# RK3399-AP register map
File version: 1
CPU: CA7 r0p1, little endian, MPU, FPU, I-cache, D-cache, VTOR, 4 interrupt priority bits, 0 interrupts
Registers are 32-bit, read-write, reset 0x0 unless marked. A register's access mark holds for its fields unless they carry their own. Offsets are from the block's base; [hi:lo] are bit positions; {n}, {i} and the like mark numbered series; 'fields as' and 'values as' point back to an identical list.

## GRF (part 4 of 4)
Base 0xFF770000
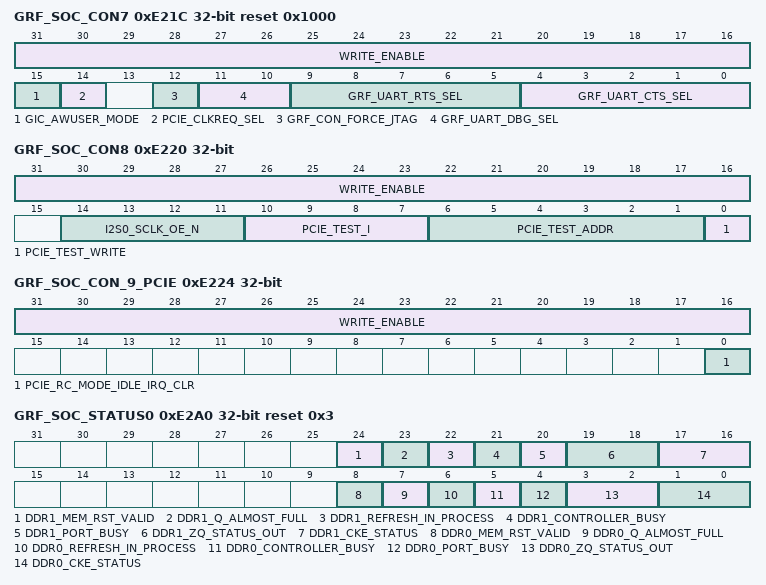
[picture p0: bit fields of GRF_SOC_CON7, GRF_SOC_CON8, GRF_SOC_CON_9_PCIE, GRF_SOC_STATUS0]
0xE21C GRF_SOC_CON7 reset 0x1000 — SoC control register 7
  [31:16] WRITE_ENABLE — bit0~15 write enable When bit 16=1, bit 0 can be written by software . When bit 16=0, bit 0 cannot be written by software; When bit 17=1, bit 1 can be written by software . When bit 17=0, bit 1 cannot be written by software; ...... When bit 31=1, bit 15 can be written by software . When bit 31=0, bit 15 cannot be written by software;
  [15] GIC_AWUSER_MODE — gic_awuser mode select 1: address mode 0: user mode
  [14] PCIE_CLKREQ_SEL — pcie_clkreq_sel port control
  [12] GRF_CON_FORCE_JTAG
  [11:10] GRF_UART_DBG_SEL
  [9:5] GRF_UART_RTS_SEL — uart_rts_sel bit control UART polarity selection for rts port Every bit for one UART. 1\'b1: invert uart_rts_n 1\'b0: keep the rts_n value from UART module output
  [4:0] GRF_UART_CTS_SEL — UART polarity selection for cts port Every bit for one UART. 1\'b1: invert uart_cts_n 1\'b0: keep the cts_n value from IO
0xE220 GRF_SOC_CON8 — SoC control register 8
  [31:16] WRITE_ENABLE — bit0~15 write enable When bit 16=1, bit 0 can be written by software . When bit 16=0, bit 0 cannot be written by software; When bit 17=1, bit 1 can be written by software . When bit 17=0, bit 1 cannot be written by software; ...... When bit 31=1, bit 15 can be written by software . When bit 31=0, bit 15 cannot be written by software;
  [14:11] I2S0_SCLK_OE_N — i2s0_sclk_oe_n bit control
  [10:7] PCIE_TEST_I — pci test input
  [6:1] PCIE_TEST_ADDR — pci test address control
  [0] PCIE_TEST_WRITE — pcie test write control 1\'b0: disable 1\'b1: enable
0xE224 GRF_SOC_CON_9_PCIE — SoC control register 9 for PCIE
  [31:16] WRITE_ENABLE — bit0~15 write enable When bit 16=1, bit 0 can be written by software . When bit 16=0, bit 0 cannot be written by software; When bit 17=1, bit 1 can be written by software . When bit 17=0, bit 1 cannot be written by software; ...... When bit 31=1, bit 15 can be written by software . When bit 31=0, bit 15 cannot be written by software;
  [0] PCIE_RC_MODE_IDLE_IRQ_CLR — irq clear bit for pcie_rc_mode_idle_irq
0xE2A0 GRF_SOC_STATUS0 reset 0x3 — SOC status register 0
  [24] DDR1_MEM_RST_VALID — status bit of ddr1_mem_rst_valid
  [23] DDR1_Q_ALMOST_FULL — status bit of ddr1_q_almost_full
  [22] DDR1_REFRESH_IN_PROCESS — status bit of ddr1_refresh_in_process
  [21] DDR1_CONTROLLER_BUSY — status bit of ddr1_controller_busy
  [20] DDR1_PORT_BUSY — status bit of ddr1_port_busy
  [19:18] DDR1_ZQ_STATUS_OUT — status bit of ddr1_zq_status_out
  [17:16] DDR1_CKE_STATUS — status bit of ddr1_cke_status
  [8] DDR0_MEM_RST_VALID — status bit of ddr0_mem_rst_valid
  [7] DDR0_Q_ALMOST_FULL — status bit of ddr0_q_almost_full
  [6] DDR0_REFRESH_IN_PROCESS — status bit of ddr0_refresh_in_process
  [5] DDR0_CONTROLLER_BUSY — status bit of ddr0_controller_busy
  [4] DDR0_PORT_BUSY — status bit of ddr0_port_busy
  [3:2] DDR0_ZQ_STATUS_OUT — status bit of ddr0_zq_status_out
  [1:0] DDR0_CKE_STATUS — status bit of ddr0_cke_status
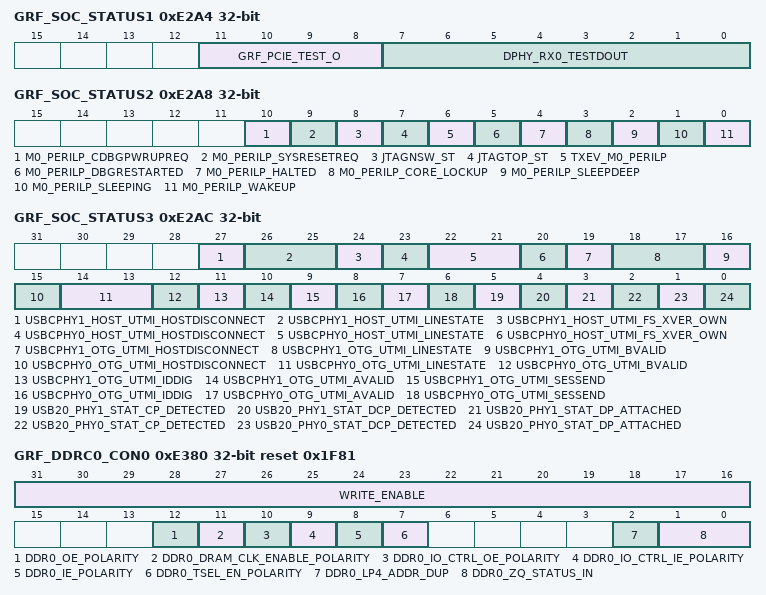
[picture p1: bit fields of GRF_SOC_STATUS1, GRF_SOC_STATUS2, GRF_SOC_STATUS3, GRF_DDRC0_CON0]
0xE2A4 GRF_SOC_STATUS1 — SOC status register 1
  [11:8] GRF_PCIE_TEST_O — status bit of grf_pcie_test_o
  [7:0] DPHY_RX0_TESTDOUT — status bit of dphy_rx0_testdout
0xE2A8 GRF_SOC_STATUS2 — SOC status register 2
  [10] M0_PERILP_CDBGPWRUPREQ — m0_perilp_cdbgpwrupreq status bit
  [9] M0_PERILP_SYSRESETREQ
  [8] JTAGNSW_ST — status bit of jtagnsw_st
  [7] JTAGTOP_ST — status bit of jtagtop_st
  [6] TXEV_M0_PERILP — status bit of xev_m0_perilp
  [5] M0_PERILP_DBGRESTARTED — status bit of m0_perilp_dbgrestarted
  [4] M0_PERILP_HALTED — status bit of m0_perilp_halted
  [3] M0_PERILP_CORE_LOCKUP — status bit of m0_perilp_core_lockup
  [2] M0_PERILP_SLEEPDEEP — status bit of m0_perilp_sleeping
  [1] M0_PERILP_SLEEPING — status bit of m0_perilp_sleeping
  [0] M0_PERILP_WAKEUP — status bit of m0_perilp_wakeup
0xE2AC GRF_SOC_STATUS3 access per field — SOC status register 3
  [27] USBCPHY1_HOST_UTMI_HOSTDISCONNECT ro — usbcphy1_host_utmi_hostdisconnect status
  [26:25] USBCPHY1_HOST_UTMI_LINESTATE ro — usbcphy1_host_utmi_linestate status
  [24] USBCPHY1_HOST_UTMI_FS_XVER_OWN ro — 1: ohci owns usb2phy 0: ehci owns usb2phy
  [23] USBCPHY0_HOST_UTMI_HOSTDISCONNECT ro — usbcphy0_host_utmi_hostdisconnect status
  [22:21] USBCPHY0_HOST_UTMI_LINESTATE ro — usbcphy0_host_utmi_linestate status
  [20] USBCPHY0_HOST_UTMI_FS_XVER_OWN ro — 1: ohci owns usb2phy 0: ehci owns usb2phy
  [19] USBCPHY1_OTG_UTMI_HOSTDISCONNECT ro — usbcphy1_otg_utmi_hostdisconnect status
  [18:17] USBCPHY1_OTG_UTMI_LINESTATE ro — usbcphy1_otg_utmi_linestate status bit
  [16] USBCPHY1_OTG_UTMI_BVALID ro — usbcphy1_otg_utmi_bvalid status bit
  [15] USBCPHY0_OTG_UTMI_HOSTDISCONNECT ro — usbcphy0_otg_utmi_hostdisconnect status
  [14:13] USBCPHY0_OTG_UTMI_LINESTATE ro — usbcphy0_otg_utmi_linestate status bit
  [12] USBCPHY0_OTG_UTMI_BVALID ro — usbcphy0_otg_utmi_bvalid status bit
  [11] USBCPHY1_OTG_UTMI_IDDIG rw — usbcphy1_otg_utmi_iddig status bit
  [10] USBCPHY1_OTG_UTMI_AVALID rw — usbcphy1_otg_utmi_avalid status bit
  [9] USBCPHY1_OTG_UTMI_SESSEND rw — usbcphy1_otg_utmi_sessend status bit
  [8] USBCPHY0_OTG_UTMI_IDDIG rw — usbcphy0_otg_utmi_iddig status bit
  [7] USBCPHY0_OTG_UTMI_AVALID rw — usbcphy0_otg_utmi_avalid status bit
  [6] USBCPHY0_OTG_UTMI_SESSEND rw — usbcphy0_otg_utmi_sessend status bit
  [5] USB20_PHY1_STAT_CP_DETECTED rw — usb20_phy1_stat_cp_detected status bit
  [4] USB20_PHY1_STAT_DCP_DETECTED rw — usb20_phy1_stat_dcp_detected status bit
  [3] USB20_PHY1_STAT_DP_ATTACHED rw — usb20_phy1_stat_dp_attached status bit
  [2] USB20_PHY0_STAT_CP_DETECTED rw — usb20_phy0_stat_cp_detected status bit
  [1] USB20_PHY0_STAT_DCP_DETECTED rw — usb20_phy0_stat_dcp_detected status bit
  [0] USB20_PHY0_STAT_DP_ATTACHED rw — usb20_phy0_stat_dp_attached status bit
0xE2B0 GRF_SOC_STATUS4 — SOC status register 4
  [31:0] DDR_MONITOR — ddr_monitor[31:0] status bit
0xE2B4 GRF_SOC_STATUS5 — SOC status register 5
  [30:0] DDR_MONITOR — ddr_monitor[62:32] status bit
0xE380 GRF_DDRC0_CON0 reset 0x1F81 — ddrc0 control register 0
  [31:16] WRITE_ENABLE — bit0~15 write enable When bit 16=1, bit 0 can be written by software . When bit 16=0, bit 0 cannot be written by software; When bit 17=1, bit 1 can be written by software . When bit 17=0, bit 1 cannot be written by software; ...... When bit 31=1, bit 15 can be written by software . When bit 31=0, bit 15 cannot be written by software;
  [12] DDR0_OE_POLARITY — bit control of ddr0_oe_polarity
  [11] DDR0_DRAM_CLK_ENABLE_POLARITY — bit control of ddr0_dram_clk_enable_polarity
  [10] DDR0_IO_CTRL_OE_POLARITY — bit control of ddr0_io_ctrl_ie_polarity
  [9] DDR0_IO_CTRL_IE_POLARITY — bit control of ddr0_io_ctrl_ie_polarity
  [8] DDR0_IE_POLARITY — bit control of ddr0_ie_polarity
  [7] DDR0_TSEL_EN_POLARITY — bit control of ddr0_tsel_en_polarity
  [2] DDR0_LP4_ADDR_DUP — bit conrol of ddr0_lp4_addr_dup
  [1:0] DDR0_ZQ_STATUS_IN — bit control of ddr0_zq_status_in
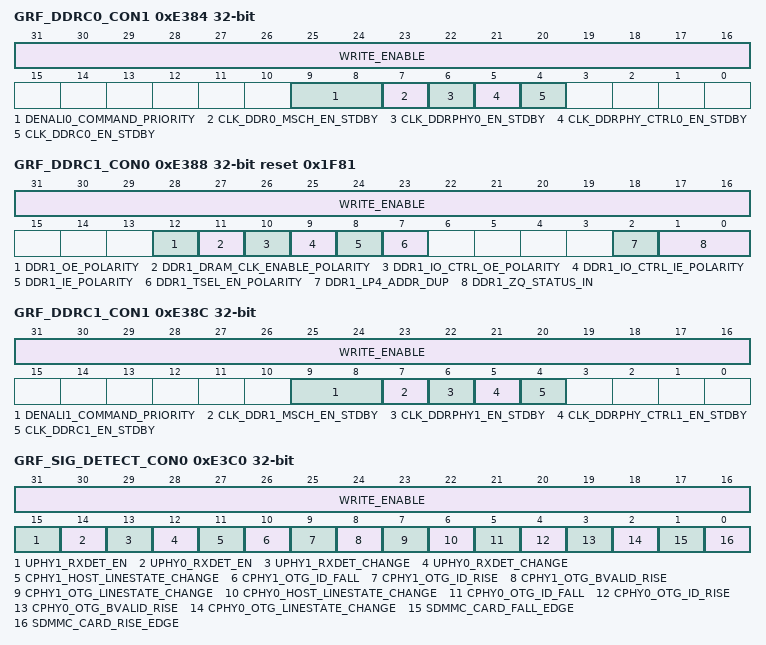
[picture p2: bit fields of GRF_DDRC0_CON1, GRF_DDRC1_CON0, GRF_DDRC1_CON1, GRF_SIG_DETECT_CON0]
0xE384 GRF_DDRC0_CON1 — ddrc0 control register 1
  [31:16] WRITE_ENABLE — bit0~15 write enable When bit 16=1, bit 0 can be written by software . When bit 16=0, bit 0 cannot be written by software; When bit 17=1, bit 1 can be written by software . When bit 17=0, bit 1 cannot be written by software; ...... When bit 31=1, bit 15 can be written by software . When bit 31=0, bit 15 cannot be written by software;
  [9:8] DENALI0_COMMAND_PRIORITY — bit control of denali0_command_priority
  [7] CLK_DDR0_MSCH_EN_STDBY — bit control of clk_ddr0_msch_en_stdby
  [6] CLK_DDRPHY0_EN_STDBY — bit control of clk_ddrphy0_en_stdby
  [5] CLK_DDRPHY_CTRL0_EN_STDBY — bit control of clk_ddrc0_en_stdby
  [4] CLK_DDRC0_EN_STDBY — bit control of clk_ddrc0_en_stdby
0xE388 GRF_DDRC1_CON0 reset 0x1F81 — ddrc1 control register 0
  [31:16] WRITE_ENABLE — bit0~15 write enable When bit 16=1, bit 0 can be written by software . When bit 16=0, bit 0 cannot be written by software; When bit 17=1, bit 1 can be written by software . When bit 17=0, bit 1 cannot be written by software; ...... When bit 31=1, bit 15 can be written by software . When bit 31=0, bit 15 cannot be written by software;
  [12] DDR1_OE_POLARITY — bit control of ddr1_oe_polarity
  [11] DDR1_DRAM_CLK_ENABLE_POLARITY — bit control of ddr1_dram_clk_enable_polarity
  [10] DDR1_IO_CTRL_OE_POLARITY — bit control of ddr1_io_ctrl_oe_polarity
  [9] DDR1_IO_CTRL_IE_POLARITY — bit control of ddr1_io_ctrl_ie_polarity
  [8] DDR1_IE_POLARITY — bit control of ddr1_ie_polarity
  [7] DDR1_TSEL_EN_POLARITY — bit control of ddr1_tsel_en_polarity
  [2] DDR1_LP4_ADDR_DUP — bit control of ddr1_lp4_addr_dup
  [1:0] DDR1_ZQ_STATUS_IN — bit control of ddr1_zq_status_in
0xE38C GRF_DDRC1_CON1 — ddrc1 control register 1
  [31:16] WRITE_ENABLE — bit0~15 write enable When bit 16=1, bit 0 can be written by software . When bit 16=0, bit 0 cannot be written by software; When bit 17=1, bit 1 can be written by software . When bit 17=0, bit 1 cannot be written by software; ...... When bit 31=1, bit 15 can be written by software . When bit 31=0, bit 15 cannot be written by software;
  [9:8] DENALI1_COMMAND_PRIORITY — bit control of denali1_command_priority
  [7] CLK_DDR1_MSCH_EN_STDBY — bit control of clk_ddr1_msch_en_stdby
  [6] CLK_DDRPHY1_EN_STDBY — bit control of clk_ddrphy1_en_stdby
  [5] CLK_DDRPHY_CTRL1_EN_STDBY — bit control of clk_ddrphy_ctrl1_en_stdby
  [4] CLK_DDRC1_EN_STDBY — bit control of clk_ddrc1_en_stdby
0xE3C0 GRF_SIG_DETECT_CON0 — Singal detect control register0
  [31:16] WRITE_ENABLE — bit0~15 write enable When bit 16=1, bit 0 can be written by software . When bit 16=0, bit 0 cannot be written by software; When bit 17=1, bit 1 can be written by software . When bit 17=0, bit 1 cannot be written by software; ...... When bit 31=1, bit 15 can be written by software . When bit 31=0, bit 15 cannot be written by software;
  [15] UPHY1_RXDET_EN — uphy1_rxdet phy conrol bit
  [14] UPHY0_RXDET_EN — uphy0_rxdet phy conrol bit
  [13] UPHY1_RXDET_CHANGE — uphy1_rxdet_change detect control 1\'b0: disbale 1\'b1: enable
  [12] UPHY0_RXDET_CHANGE — uphy0_rxdet_change detect control 1\'b0: disbale 1\'b1: enable
  [11] CPHY1_HOST_LINESTATE_CHANGE — cphy1_host_linestate_change detect control 1\'b0: disbale 1\'b1: enable
  [10] CPHY1_OTG_ID_FALL — cphy1_otg_id_fall detect control 1\'b0: disbale 1\'b1: enable
  [9] CPHY1_OTG_ID_RISE — cphy1_otg_id_rise detect control 1\'b0: disbale 1\'b1: enable
  [8] CPHY1_OTG_BVALID_RISE — cphy1_otg_bvalid_rise detect control 1\'b0: disbale 1\'b1: enable
  [7] CPHY1_OTG_LINESTATE_CHANGE — cphy1_otg_linestate_change detect control 1\'b0: disbale 1\'b1: enable
  [6] CPHY0_HOST_LINESTATE_CHANGE — cphy0_host_linestate_change detect control 1\'b0: disbale 1\'b1: enable
  [5] CPHY0_OTG_ID_FALL — cphy0_otg_id_fall detect control 1\'b0: disbale 1\'b1: enable
  [4] CPHY0_OTG_ID_RISE — cphy0_otg_id_rise detect control 1\'b0: disbale 1\'b1: enable
  [3] CPHY0_OTG_BVALID_RISE — cphy0_otg_bvalid_rise detect control 1\'b0: disbale 1\'b1: enable
  [2] CPHY0_OTG_LINESTATE_CHANGE — cphy0_otg_linestate_change detect control 1\'b0: disbale 1\'b1: enable
  [1] SDMMC_CARD_FALL_EDGE — sdmmc card fall edge detect control 1\'b0: disbale 1\'b1: enable
  [0] SDMMC_CARD_RISE_EDGE — sdmmc card rise edge detect control 1\'b0: disbale 1\'b1: enable
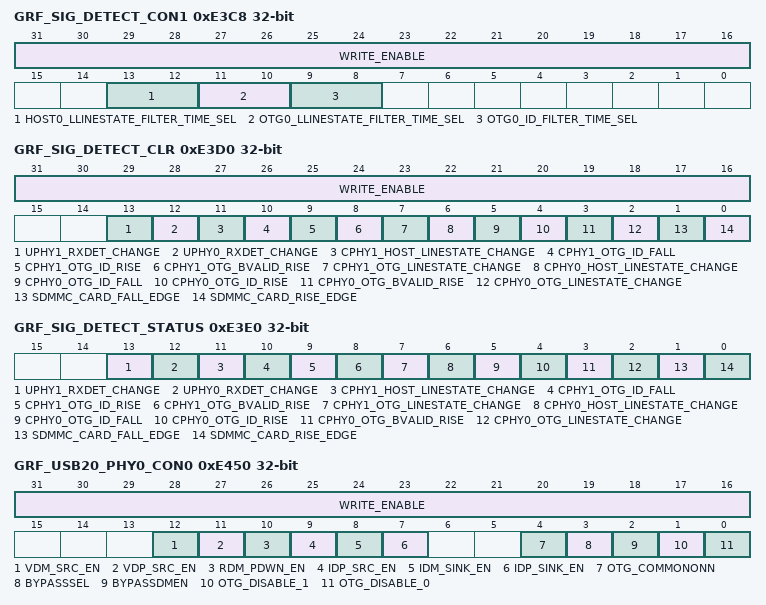
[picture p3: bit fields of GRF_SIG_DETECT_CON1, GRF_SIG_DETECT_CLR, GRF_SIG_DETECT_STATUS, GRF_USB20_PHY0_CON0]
0xE3C8 GRF_SIG_DETECT_CON1 — Singal detect control register1
  [31:16] WRITE_ENABLE — bit0~15 write enable When bit 16=1, bit 0 can be written by software . When bit 16=0, bit 0 cannot be written by software; When bit 17=1, bit 1 can be written by software . When bit 17=0, bit 1 cannot be written by software; ...... When bit 31=1, bit 15 can be written by software . When bit 31=0, bit 15 cannot be written by software;
  [13:12] HOST0_LLINESTATE_FILTER_TIME_SEL — filter time select 00: 100us 01: 500us 10: 1ms 11: 10ms
  [11:10] OTG0_LLINESTATE_FILTER_TIME_SEL — filter time select 00: 100us 01: 500us 10: 1ms 11: 10ms
  [9:8] OTG0_ID_FILTER_TIME_SEL — filter time select 00: 5ms 01: 15ms 10: 35ms 11: 50ms
0xE3D0 GRF_SIG_DETECT_CLR — Signal detect status clear register
  [31:16] WRITE_ENABLE — bit0~15 write enable When bit 16=1, bit 0 can be written by software . When bit 16=0, bit 0 cannot be written by software; When bit 17=1, bit 1 can be written by software . When bit 17=0, bit 1 cannot be written by software; ...... When bit 31=1, bit 15 can be written by software . When bit 31=0, bit 15 cannot be written by software;
  [13] UPHY1_RXDET_CHANGE — uphy1_rxdet_change detect control 1\'b0: disbale 1\'b1: enable
  [12] UPHY0_RXDET_CHANGE — uphy0_rxdet_change detect control 1\'b0: disbale 1\'b1: enable
  [11] CPHY1_HOST_LINESTATE_CHANGE — cphy1_host_linestate_change detect control 1\'b0: disbale 1\'b1: enable
  [10] CPHY1_OTG_ID_FALL — cphy1_otg_id_fall detect control 1\'b0: disbale 1\'b1: enable
  [9] CPHY1_OTG_ID_RISE — cphy1_otg_id_rise detect control 1\'b0: disbale 1\'b1: enable
  [8] CPHY1_OTG_BVALID_RISE — cphy1_otg_bvalid_rise detect control 1\'b0: disbale 1\'b1: enable
  [7] CPHY1_OTG_LINESTATE_CHANGE — cphy1_otg_linestate_change detect control 1\'b0: disbale 1\'b1: enable
  [6] CPHY0_HOST_LINESTATE_CHANGE — cphy0_host_linestate_change detect control 1\'b0: disbale 1\'b1: enable
  [5] CPHY0_OTG_ID_FALL — cphy0_otg_id_fall detect control 1\'b0: disbale 1\'b1: enable
  [4] CPHY0_OTG_ID_RISE — cphy0_otg_id_rise detect control 1\'b0: disbale 1\'b1: enable
  [3] CPHY0_OTG_BVALID_RISE — cphy0_otg_bvalid_rise detect control 1\'b0: disbale 1\'b1: enable
  [2] CPHY0_OTG_LINESTATE_CHANGE — cphy0_otg_linestate_change detect control 1\'b0: disbale 1\'b1: enable
  [1] SDMMC_CARD_FALL_EDGE — sdmmc card fall edge detect control 1\'b0: disbale 1\'b1: enable
  [0] SDMMC_CARD_RISE_EDGE — sdmmc card rise edge detect control 1\'b0: disbale 1\'b1: enable
0xE3E0 GRF_SIG_DETECT_STATUS — Signal detect status register
  [13] UPHY1_RXDET_CHANGE — uphy1_rxdet_change detect status
  [12] UPHY0_RXDET_CHANGE — uphy0_rxdet_change detect status
  [11] CPHY1_HOST_LINESTATE_CHANGE — cphy1_host_linestate_change detect status
  [10] CPHY1_OTG_ID_FALL — cphy1_otg_id_fall detect status
  [9] CPHY1_OTG_ID_RISE — cphy1_otg_id_rise detect status
  [8] CPHY1_OTG_BVALID_RISE — cphy1_otg_bvalid_rise detect status
  [7] CPHY1_OTG_LINESTATE_CHANGE — cphy1_otg_linestate_change detect status
  [6] CPHY0_HOST_LINESTATE_CHANGE — cphy0_host_linestate_change detect status
  [5] CPHY0_OTG_ID_FALL — cphy0_otg_id_fall detect status
  [4] CPHY0_OTG_ID_RISE — cphy0_otg_id_rise detect status
  [3] CPHY0_OTG_BVALID_RISE — cphy0_otg_bvalid_rise detect status
  [2] CPHY0_OTG_LINESTATE_CHANGE — cphy0_otg_linestate_change detect status
  [1] SDMMC_CARD_FALL_EDGE — sdmmc card fall edge detect status
  [0] SDMMC_CARD_RISE_EDGE — sdmmc card rise edge detect status
0xE450 GRF_USB20_PHY0_CON0 — USB20 PHY0 GRF Register 0
  [31:16] WRITE_ENABLE — bit0~15 write enable When bit 16=1, bit 0 can be written by software . When bit 16=0, bit 0 cannot be written by software; When bit 17=1, bit 1 can be written by software . When bit 17=0, bit 1 cannot be written by software; ...... When bit 31=1, bit 15 can be written by software . When bit 31=0, bit 15 cannot be written by software;
  [12] VDM_SRC_EN — vdm_src_en 1: enable vdm_src for battery charge for usb3otg0
  [11] VDP_SRC_EN — vdp_src_en 1:enable vdp_src for battery charge for usb3otg0
  [10] RDM_PDWN_EN — rdm_pdwn_en 1: enable rdm_pdwn for battery charge for usb3otg0
  [9] IDP_SRC_EN — idp_src_en 1: enable idp_src for battery charge for usb3otg0
  [8] IDM_SINK_EN — idm_sink_en 1: enable idm_sink for battery charge for usb3otg0
  [7] IDP_SINK_EN — idp_sink_en 1: enable idp_sink for battery charge for usb3otg0
  [4] OTG_COMMONONN — otg_commononn configure pll clock output in suspend mode
  [3] BYPASSSEL — bypasssel 1: bypass DP/DM as uart sin/sout for usb3otg0 0: Normal USB function for usb3otg0
  [2] BYPASSDMEN — bypassdmen 1: enable bypass uart_sout to DM for usb3otg0 0: disable bypass uart_sout to DM for usb3otg0
  [1] OTG_DISABLE_1 — otg_disable_1 1:disable otg function of usb20 host0 0:enable otg function of usb20 host0
  [0] OTG_DISABLE_0 — otg_disable_0 1:disable otg function of usb3otg0 0:enable otg function of usb3otg0
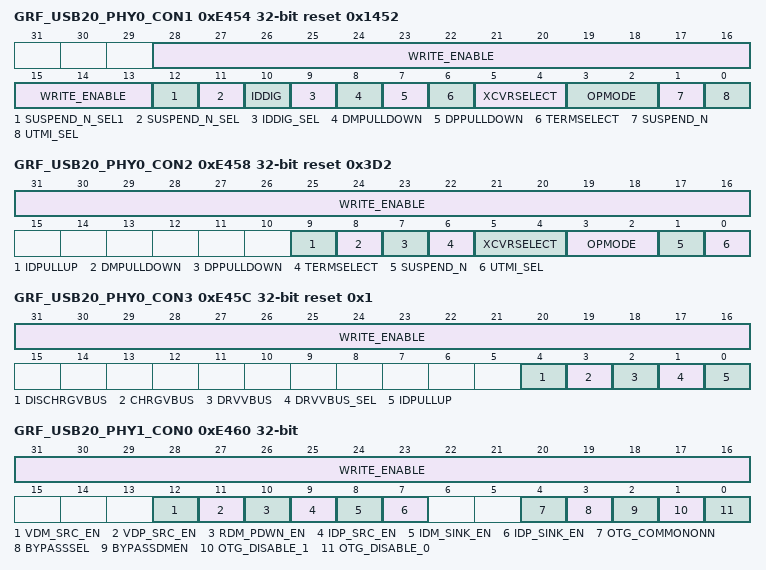
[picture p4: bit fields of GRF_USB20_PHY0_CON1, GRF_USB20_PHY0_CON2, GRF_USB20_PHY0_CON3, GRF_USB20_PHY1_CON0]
0xE454 GRF_USB20_PHY0_CON1 reset 0x1452 — USB20 PHY0 GRF Register 1
  [28:13] WRITE_ENABLE — bit0~15 write enable When bit 16=1, bit 0 can be written by software . When bit 16=0, bit 0 cannot be written by software; When bit 17=1, bit 1 can be written by software . When bit 17=0, bit 1 cannot be written by software; ...... When bit 31=1, bit 15 can be written by software . When bit 31=0, bit 15 cannot be written by software;
  [12] SUSPEND_N_SEL1 — suspend_n_sel1 Pls see suspend_n.
  [11] SUSPEND_N_SEL — suspend_n_sel Pls see suspend_n.
  [10] IDDIG — iddig Select the value of this register to usb3otg0 register
  [9] IDDIG_SEL — iddig_sel 1: select the value of bit10 of USB20_PHY0_CON1 to usb3otg0 controller 0: select the iddig from usb2phy to usb3otg0 controller
  [8] DMPULLDOWN — dmpulldown Select the value of this register to usb2phy when utmi_sel=1
  [7] DPPULLDOWN — dppulldown Select the value of this register to usb2phy when utmi_sel=1
  [6] TERMSELECT — termselect Select the value of this register to usb2phy when utmi_sel=1
  [5:4] XCVRSELECT — xcvrselect Select the value of this register to usb2phy when utmi_sel=1
  [3:2] OPMODE — opmode Select the value of this register to usb2phy when utmi_sel=1
  [1] SUSPEND_N — suspend_n utmi_sel=1, select the value of this register to usb2phy utmi_sel=0 and bit11 of USB20_PHY0_CON1=0, and bit 12 of USB20_PHY0_CON1=0 select the value of the value of this bit to usb2phy utmi_sel=0 and bit11 of USB20_PHY0_CON1=0, and bit 12 of USB20_PHY0_CON1=1 select suspend_n signals from usb3otg0 controller to usb2phy for free running utmi clock utmi_sel=0 and bit11 of USB20_PHY0_CON1=1, select suspend_com_n signals from usb3otg0 controller to usb2phy for not free running utmi clock
  [0] UTMI_SEL — utmi_sel 1: select utmi interface signals from GRF reister to usb2phy 0: select utmi interface signals from utmi interface of usb3otg0 controller to usb2phy
0xE458 GRF_USB20_PHY0_CON2 reset 0x3D2 — USB20 PHY0 GRF Register 2
  [31:16] WRITE_ENABLE — bit0~15 write enable When bit 16=1, bit 0 can be written by software . When bit 16=0, bit 0 cannot be written by software; When bit 17=1, bit 1 can be written by software . When bit 17=0, bit 1 cannot be written by software; ...... When bit 31=1, bit 15 can be written by software . When bit 31=0, bit 15 cannot be written by software;
  [9] IDPULLUP — idpullup Use the value of this register input to idpullup of usb2phy
  [8] DMPULLDOWN — dmpulldown Use the value of this register input to dmpulldown of usb2phy
  [7] DPPULLDOWN — dppulldown Use the value of this register input to dppulldown of usb2phy
  [6] TERMSELECT — termselect Select the value of this register to usb2phy when utmi_sel=1
  [5:4] XCVRSELECT — xcvrselect Select the value of this register to usb2phy when utmi_sel=1
  [3:2] OPMODE — opmode Select the value of this register to usb2phy when utmi_sel=1
  [1] SUSPEND_N — suspend_n Select the value of this register to usb2phy when utmi_sel=1
  [0] UTMI_SEL — utmi_sel 1: select utmi interface signals from GRF reister to usb2phy 0: select utmi interface signals from utmi interface of usb20 host0 controller to usb2phy
0xE45C GRF_USB20_PHY0_CON3 reset 0x1 — USB20 PHY0 GRF Register 3
  [31:16] WRITE_ENABLE — bit0~15 write enable When bit 16=1, bit 0 can be written by software . When bit 16=0, bit 0 cannot be written by software; When bit 17=1, bit 1 can be written by software . When bit 17=0, bit 1 cannot be written by software; ...... When bit 31=1, bit 15 can be written by software . When bit 31=0, bit 15 cannot be written by software;
  [4] DISCHRGVBUS — dischrgvbus Use the value of this register input to chrgvbus of usb2phy
  [3] CHRGVBUS — chrgvbus Use the value of this register input to chrgvbus of usb2phy
  [2] DRVVBUS — drvvbus Pls see drvvbus_sel.
  [1] DRVVBUS_SEL — drvvbus_sel 1: select the value of bit2 of USB20_PHY0_CON3 to drvvbus of usb2phy and GPIO to external PMIC 0: select drvvbus from usb3otg0 controller to drvvbus of usb2phy and GPIO to external PMIC
  [0] IDPULLUP — idpullup Use the value of this register input to idpullup of usb2phy
0xE460 GRF_USB20_PHY1_CON0 — USB20 PHY1 GRF Register 0
  [31:16] WRITE_ENABLE — bit0~15 write enable When bit 16=1, bit 0 can be written by software . When bit 16=0, bit 0 cannot be written by software; When bit 17=1, bit 1 can be written by software . When bit 17=0, bit 1 cannot be written by software; ...... When bit 31=1, bit 15 can be written by software . When bit 31=0, bit 15 cannot be written by software;
  [12] VDM_SRC_EN — vdm_src_en 1: enable vdm_src for battery charge for usb3otg1
  [11] VDP_SRC_EN — vdp_src_en 1:enable vdp_src for battery charge for usb3otg1
  [10] RDM_PDWN_EN — rdm_pdwn_en 1: enable rdm_pdwn for battery charge for usb3otg1
  [9] IDP_SRC_EN — idp_src_en 1: enable idp_src for battery charge for usb3otg1
  [8] IDM_SINK_EN — idm_sink_en 1: enable idm_sink for battery charge for usb3otg1
  [7] IDP_SINK_EN — idp_sink_en 1: enable idp_sink for battery charge for usb3otg1
  [4] OTG_COMMONONN — otg_commononn configure pll clock output in suspend mode
  [3] BYPASSSEL — bypasssel 1: bypass DP/DM as uart sin/sout for usb3otg1 0: Normal USB function for usb3otg1
  [2] BYPASSDMEN — bypassdmen 1: enable bypass uart_sout to DM for usb3otg1 0: disable bypass uart_sout to DM for usb3otg1
  [1] OTG_DISABLE_1 — otg_disable_1 1:disable otg function of usb2 host1 0:enable otg function of usb2 host1
  [0] OTG_DISABLE_0 — otg_disable_0 1:disable otg function of usb3otg1 0:enable otg function of usb3otg1
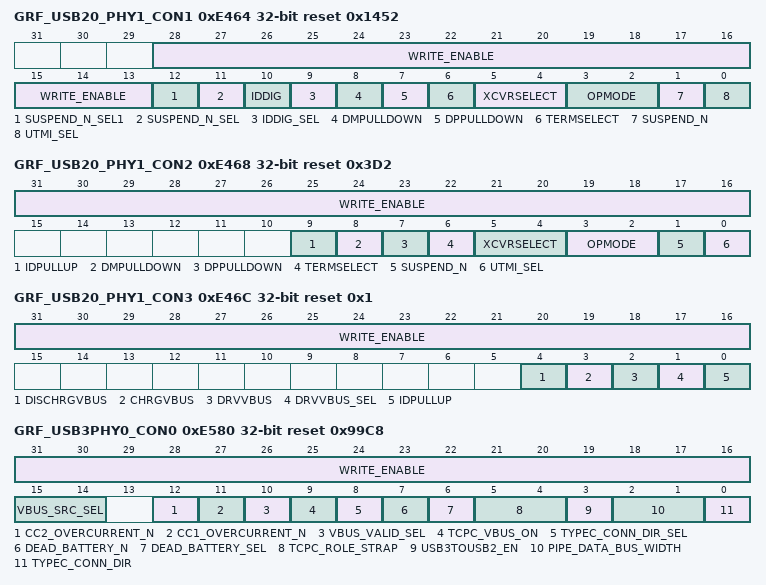
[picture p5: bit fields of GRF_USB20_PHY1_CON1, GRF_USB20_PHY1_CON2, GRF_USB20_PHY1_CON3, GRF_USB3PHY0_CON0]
0xE464 GRF_USB20_PHY1_CON1 reset 0x1452 — USB20 PHY1GRF Register 1
  [28:13] WRITE_ENABLE — bit0~15 write enable When bit 16=1, bit 0 can be written by software . When bit 16=0, bit 0 cannot be written by software; When bit 17=1, bit 1 can be written by software . When bit 17=0, bit 1 cannot be written by software; ...... When bit 31=1, bit 15 can be written by software . When bit 31=0, bit 15 cannot be written by software;
  [12] SUSPEND_N_SEL1 — suspend_n-_sel1 Pls see suspend_n.
  [11] SUSPEND_N_SEL — suspend_n_sel Pls see suspend_n.
  [10] IDDIG — iddig Select the value of this register to usb3otg1 register
  [9] IDDIG_SEL — iddig_sel 1: select the value of bit10 of USB20_PHY0_CON1 to usb3otg1 controller 0: select the iddig from usb2phy to usb3otg1 controller
  [8] DMPULLDOWN — dmpulldown Select the value of this register to usb2phy when utmi_sel=1
  [7] DPPULLDOWN — dppulldown Select the value of this register to usb2phy when utmi_sel=1
  [6] TERMSELECT — termselect Select the value of this register to usb2phy when utmi_sel=1
  [5:4] XCVRSELECT — xcvrselect Select the value of this register to usb2phy when utmi_sel=1
  [3:2] OPMODE — opmode Select the value of this register to usb2phy when utmi_sel=1
  [1] SUSPEND_N — suspend_n utmi_sel=1, select the value of this register to usb2phy utmi_sel=0 and bit11 of USB20_PHY0_CON1=0, and bit 12 of USB20_PHY0_CON1=0 select the value of the value of this bit to usb2phy utmi_sel=0 and bit11 of USB20_PHY0_CON1=0, and bit 12 of USB20_PHY0_CON1=1 select suspend_n signals from usb3otg0 controller to usb2phy for free running utmi clock utmi_sel=0 and bit11 of USB20_PHY0_CON1=1, select suspend_com_n signals from usb3otg0 controller to usb2phy for not free running utmi clock
  [0] UTMI_SEL — utmi_sel 1: select utmi interface signals from GRF reister to usb2phy 0: select utmi interface signals from utmi interface of usb3otg1 controller to usb2phy
0xE468 GRF_USB20_PHY1_CON2 reset 0x3D2 — USB20 PHY1 GRF Register 2
  [31:16] WRITE_ENABLE — bit0~15 write enable When bit 16=1, bit 0 can be written by software . When bit 16=0, bit 0 cannot be written by software; When bit 17=1, bit 1 can be written by software . When bit 17=0, bit 1 cannot be written by software; ...... When bit 31=1, bit 15 can be written by software . When bit 31=0, bit 15 cannot be written by software;
  [9] IDPULLUP — idpullup Use the value of this register input to idpullup of usb2phy
  [8] DMPULLDOWN — dmpulldown Use the value of this register input to dmpulldown of usb2phy
  [7] DPPULLDOWN — dppulldown Use the value of this register input to dppulldown of usb2phy
  [6] TERMSELECT — termselect Select the value of this register to usb2phy when utmi_sel=1
  [5:4] XCVRSELECT — xcvrselect Select the value of this register to usb2phy when utmi_sel=1
  [3:2] OPMODE — opmode Select the value of this register to usb2phy when utmi_sel=1
  [1] SUSPEND_N — suspend_n Select the value of this register to usb2phy when utmi_sel=1
  [0] UTMI_SEL — utmi_sel 1: select utmi interface signals from GRF reister to usb2phy 0: select utmi interface signals from utmi interface of usb20 host1 controller to usb2phy
0xE46C GRF_USB20_PHY1_CON3 reset 0x1 — USB20 PHY1 GRF Register 3
  [31:16] WRITE_ENABLE — bit0~15 write enable When bit 16=1, bit 0 can be written by software . When bit 16=0, bit 0 cannot be written by software; When bit 17=1, bit 1 can be written by software . When bit 17=0, bit 1 cannot be written by software; ...... When bit 31=1, bit 15 can be written by software . When bit 31=0, bit 15 cannot be written by software;
  [4] DISCHRGVBUS — dischrgvbus Use the value of this register input to chrgvbus of usb2phy
  [3] CHRGVBUS — chrgvbus Use the value of this register input to chrgvbus of usb2phy
  [2] DRVVBUS — drvvbus Pls see drvvbus_sel.
  [1] DRVVBUS_SEL — drvvbus_sel 1: select the value of bit2 of USB20_PHY1_CON3 to drvvbus of usb2phy and GPIO to external PMIC 0: select drvvbus from usb3otg1 controller to drvvbus of usb2phy and GPIO to external PMIC
  [0] IDPULLUP — idpullup Use the value of this register input to idpullup of usb2phy
0xE580 GRF_USB3PHY0_CON0 reset 0x99C8 — TypeC PHY/TCPD PHY/TCPC Control register0
  [31:16] WRITE_ENABLE — bit0~15 write enable When bit 16=1, bit 0 can be written by software . When bit 16=0, bit 0 cannot be written by software; When bit 17=1, bit 1 can be written by software . When bit 17=0, bit 1 cannot be written by software; ...... When bit 31=1, bit 15 can be written by software . When bit 31=0, bit 15 cannot be written by software;
  [15:14] VBUS_SRC_SEL — vbus source select to IOMUX 0: select vbus_source_en of TCPC0 to IOMUX 1: select vbus_source_en of TCPC1 to IOMUX 2: select host0_drvvbus, host1_drvvbus, otg0_drvvbus, otg1_drvvbus to IOMUX
  [12] CC2_OVERCURRENT_N — cc2 overcurrent 0: cc2 overcurrent 1: cc2 not overcurrent
  [11] CC1_OVERCURRENT_N — cc1 overcurrent 0: cc1 overcurrent 1: cc1 not overcurrent
  [10] VBUS_VALID_SEL — vbus valid select 0: use bvalid from usb2phy to usb3 controller 1: usb vbus_valid from TCPC to usb3 controller
  [9] TCPC_VBUS_ON — TCPC Vbus On 0: disable TCPC vbus supply 1: enable TCPC vbus supply
  [8] TYPEC_CONN_DIR_SEL — TypeC connect direction select 0: select typec_conn_dir (bit0 of this register) to TypeC PHY 1: select TCPC ouput typec_con_dir to TypeC PHY
  [7] DEAD_BATTERY_N — dead_battery_n 1: no dead battery 0: dead battery
  [6] DEAD_BATTERY_SEL — dead_battery_sel 0: select external dead_battery_n from IOMUX 1: select internal bit7 of this register
  [5:4] TCPC_ROLE_STRAP — TCPC role trap 01: TCPC default as DFP 10: TCPC default as UFP 11: TCPC default as DRP
  [3] USB3TOUSB2_EN — force usb3 to usb2 enable control 1: force usb3 controller work as usb2. 0: not force usb3 controller work as usb2.
  [2:1] PIPE_DATA_BUS_WIDTH — Pipe interface data bus width 0: 32bit data bus width, only support 32bit data bus width.
  [0] TYPEC_CONN_DIR — TypeC PHY connect direction 0: normal orientation 1: flip orientation
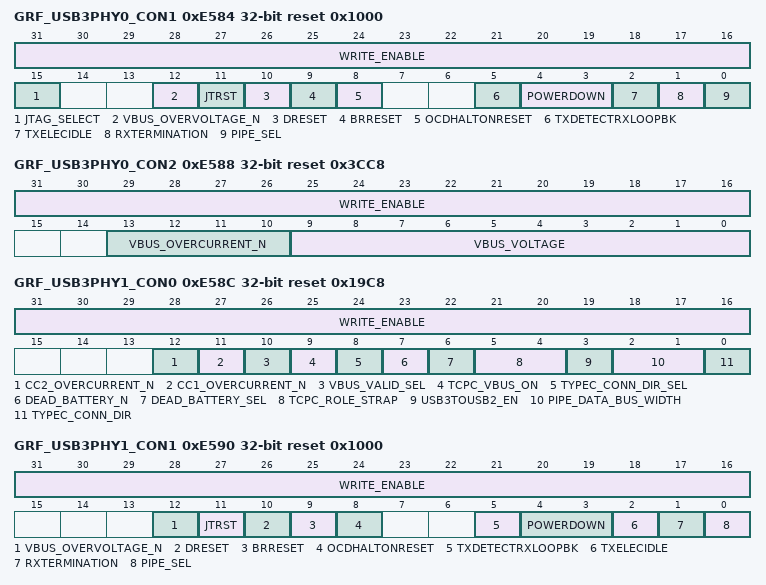
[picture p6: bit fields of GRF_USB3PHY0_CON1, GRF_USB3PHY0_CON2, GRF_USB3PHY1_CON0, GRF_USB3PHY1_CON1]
0xE584 GRF_USB3PHY0_CON1 reset 0x1000 — TypeC PHY/TCPD PHY/TCPC Control register1
  [31:16] WRITE_ENABLE — bit0~15 write enable When bit 16=1, bit 0 can be written by software . When bit 16=0, bit 0 cannot be written by software; When bit 17=1, bit 1 can be written by software . When bit 17=0, bit 1 cannot be written by software; ...... When bit 31=1, bit 15 can be written by software . When bit 31=0, bit 15 cannot be written by software;
  [15] JTAG_SELECT — JTAG_select 0: select TDO of TCPC0 to IOMUX 1: select TDO of TCPC1 to IOMUX
  [12] VBUS_OVERVOLTAGE_N — vbus overvoltage 0: vbus over voltage 1: vbus not over voltage
  [11] JTRST — JTRST TCPC extensa core JTAG JTRST reset control
  [10] DRESET — DReset TCPC extensa core JTAG DReset
  [9] BRRESET — BRreset TCPC extensa core JTAG BRreset
  [8] OCDHALTONRESET — OCDHaltOnReset TCPC extensa core JTAG OCDHaltOnReset
  [5] TXDETECTRXLOOPBK — txdetectrxloopbk pipe_sel=1, select this bit to TypeC PHY
  [4:3] POWERDOWN — powerdown pipe_sel: select this two bit to TypeC PHY
  [2] TXELECIDLE — txelecidle pipe_sel=1, select this bit to TypeC PHY
  [1] RXTERMINATION — rx termination pipe_sel=1, select this bit to TypeC PHY
  [0] PIPE_SEL — pipe interface select 0: select pipe interface from usb3otg 1: select pipe interface from grf controller register
0xE588 GRF_USB3PHY0_CON2 reset 0x3CC8 — TypeC PHY/TCPD PHY/TCPC Control register2
  [31:16] WRITE_ENABLE — bit0~15 write enable When bit 16=1, bit 0 can be written by software . When bit 16=0, bit 0 cannot be written by software; When bit 17=1, bit 1 can be written by software . When bit 17=0, bit 1 cannot be written by software; ...... When bit 31=1, bit 15 can be written by software . When bit 31=0, bit 15 cannot be written by software;
  [13:10] VBUS_OVERCURRENT_N — vbus source overcurrent 0: vbus source over current 1: vbus source not over current
  [9:0] VBUS_VOLTAGE — TCPC vbus voltage TCPC vbus voltage
0xE58C GRF_USB3PHY1_CON0 reset 0x19C8 — TypeC PHY/TCPD PHY/TCPC Control register0
  [31:16] WRITE_ENABLE — bit0~15 write enable When bit 16=1, bit 0 can be written by software . When bit 16=0, bit 0 cannot be written by software; When bit 17=1, bit 1 can be written by software . When bit 17=0, bit 1 cannot be written by software; ...... When bit 31=1, bit 15 can be written by software . When bit 31=0, bit 15 cannot be written by software;
  [12] CC2_OVERCURRENT_N — cc2 overcurrent 0: cc2 overcurrent 1: cc2 not overcurrent
  [11] CC1_OVERCURRENT_N — cc1 overcurrent 0: cc1 overcurrent 1: cc1 not overcurrent
  [10] VBUS_VALID_SEL — vbus valid select 0: use bvalid from usb2phy to usb3 controller 1: usb vbus_valid from TCPC to usb3 controller
  [9] TCPC_VBUS_ON — TCPC Vbus On 0: disable TCPC vbus supply 1: enable TCPC vbus supply
  [8] TYPEC_CONN_DIR_SEL — TypeC connect direction select 0: select typec_conn_dir (bit0 of this register) to TypeC PHY 1: select TCPC ouput typec_con_dir to TypeC PHY
  [7] DEAD_BATTERY_N — dead_battery_n 1: no dead battery 0: dead battery
  [6] DEAD_BATTERY_SEL — dead_battery_sel 0: select external dead_battery_n from IOMUX 1: select internal bit7 of this register
  [5:4] TCPC_ROLE_STRAP — TCPC role trap 01: TCPC default as DFP 10: TCPC default as UFP 11: TCPC default as DRP
  [3] USB3TOUSB2_EN — force usb3 to usb2 enable control 1: force usb3 controller work as usb2. 0: not force usb3 controller work as usb2.
  [2:1] PIPE_DATA_BUS_WIDTH — Pipe interface data bus width 0: 32bit data bus width, only support 32bit data bus width.
  [0] TYPEC_CONN_DIR — TypeC PHY connect direction 0: normal orientation 1: flip orientation
0xE590 GRF_USB3PHY1_CON1 reset 0x1000 — TypeC PHY/TCPD PHY/TCPC Control register1
  [31:16] WRITE_ENABLE — bit0~15 write enable When bit 16=1, bit 0 can be written by software . When bit 16=0, bit 0 cannot be written by software; When bit 17=1, bit 1 can be written by software . When bit 17=0, bit 1 cannot be written by software; ...... When bit 31=1, bit 15 can be written by software . When bit 31=0, bit 15 cannot be written by software;
  [12] VBUS_OVERVOLTAGE_N — vbus overvoltage 0: vbus over voltage 1: vbus not over voltage
  [11] JTRST — JTRST TCPC extensa core JTAG JTRST reset control
  [10] DRESET — DReset TCPC extensa core JTAG DReset
  [9] BRRESET — BRreset TCPC extensa core JTAG BRreset
  [8] OCDHALTONRESET — OCDHaltOnReset TCPC extensa core JTAG OCDHaltOnReset
  [5] TXDETECTRXLOOPBK — txdetectrxloopbk pipe_sel=1, select this bit to TypeC PHY
  [4:3] POWERDOWN — powerdown pipe_sel: select this two bit to TypeC PHY
  [2] TXELECIDLE — txelecidle pipe_sel=1, select this bit to TypeC PHY
  [1] RXTERMINATION — rx termination pipe_sel=1, select this bit to TypeC PHY
  [0] PIPE_SEL — pipe interface select 0: select pipe interface from usb3otg 1: select pipe interface from grf controller register
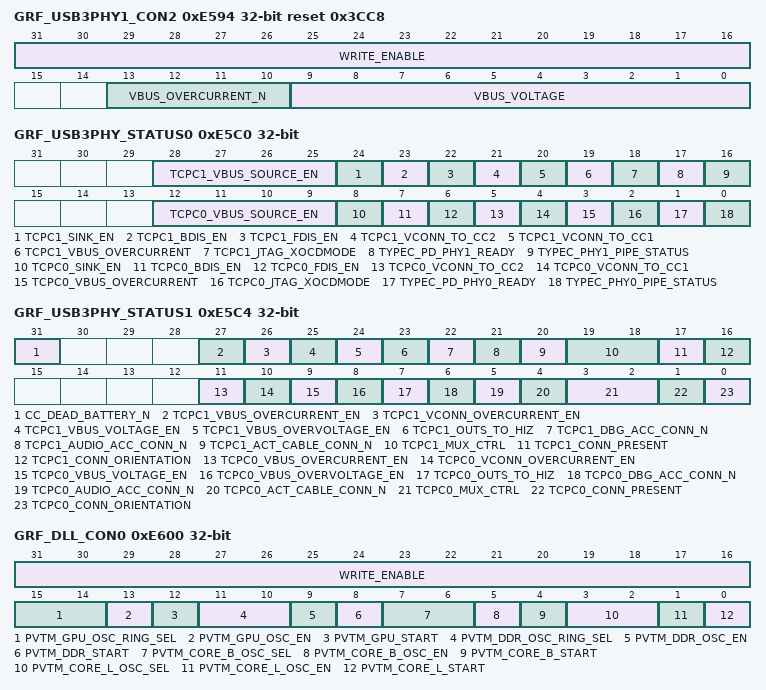
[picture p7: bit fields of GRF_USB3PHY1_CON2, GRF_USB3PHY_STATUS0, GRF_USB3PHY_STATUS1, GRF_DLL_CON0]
0xE594 GRF_USB3PHY1_CON2 reset 0x3CC8 — TypeC PHY/TCPD PHY/TCPC Control register2
  fields as GRF_USB3PHY0_CON2
0xE5C0 GRF_USB3PHY_STATUS0 access per field — USB3PHY_STATUS0
  [28:25] TCPC1_VBUS_SOURCE_EN ro — TCPC1_vbus_source_en 1: select corresponding vbus source
  [24] TCPC1_SINK_EN rw — TCPC1_sink_en 1: TCPC1 enable to sink vbus
  [23] TCPC1_BDIS_EN rw — TCPC1_bdis_en 1: TCPC1 bleed discharge enable
  [22] TCPC1_FDIS_EN rw — TCPC1_fdis_en 1: TCPC1 force discharge enable
  [21] TCPC1_VCONN_TO_CC2 ro — TCPC1 supply VCONN to CC2 1: TCPC1 supply VCONN to CC2
  [20] TCPC1_VCONN_TO_CC1 ro — TCPC1 vconn supply to CC1 1: support voconn to CC1
  [19] TCPC1_VBUS_OVERCURRENT ro — TCPC1 vbus overcurrent ouput 1: vbus over current
  [18] TCPC1_JTAG_XOCDMODE ro
  [17] TYPEC_PD_PHY1_READY ro — TypeC PD PHY 1 ready 1: TypeC PD PHY ready
  [16] TYPEC_PHY1_PIPE_STATUS ro — TypeC PHY 0 pipe status 0: indicate TypeC PHY pipe ready after release TypeC PHY pipe reset.
  [12:9] TCPC0_VBUS_SOURCE_EN ro — TCPC0_vbus_source_en 1: select corresponding vbus source
  [8] TCPC0_SINK_EN ro — TCPC0_sink_en 1: TCPC0 enable to sink vbus
  [7] TCPC0_BDIS_EN ro — TCPC0_bdis_en 1: TCPC0 bleed discharge enable
  [6] TCPC0_FDIS_EN ro — TCPC0_fdis_en 1: TCPC0 force discharge enable
  [5] TCPC0_VCONN_TO_CC2 ro — TCPC0 supply VCONN to CC2 1: TCPC0 supply VCONN to CC2
  [4] TCPC0_VCONN_TO_CC1 ro — TCPC0 vconn supply to CC1 1: support voconn to CC1
  [3] TCPC0_VBUS_OVERCURRENT ro — TCPC0 vbus overcurrent ouput 1: vbus over current
  [2] TCPC0_JTAG_XOCDMODE ro
  [1] TYPEC_PD_PHY0_READY ro — TypeC PD PHY 0 ready 1: TypeC PD PHY ready
  [0] TYPEC_PHY0_PIPE_STATUS ro — TypeC PHY 0 pipe status 0: indicate TypeC PHY pipe ready after release TypeC PHY pipe reset.
0xE5C4 GRF_USB3PHY_STATUS1 access per field — USB3PHY_STATUS1
  [31] CC_DEAD_BATTERY_N ro — CC dead battery indicator from IOMUX 0: dead battery happen 1: No dead battery happen
  [27] TCPC1_VBUS_OVERCURRENT_EN rw — TCPC vbus over current enable 1: enable
  [26] TCPC1_VCONN_OVERCURRENT_EN ro — TCPC vconn overcurrent enable 1: enable
  [25] TCPC1_VBUS_VOLTAGE_EN ro — TCPC vbus voltage enable 1: enable
  [24] TCPC1_VBUS_OVERVOLTAGE_EN ro — TCPC vbus overvoltage enable 1: enable
  [23] TCPC1_OUTS_TO_HIZ ro — TCPC outs to hiz
  [22] TCPC1_DBG_ACC_CONN_N ro — TCPC debug accessory connect 0: Debug accessory connected 1: No debug accessory connected
  [21] TCPC1_AUDIO_ACC_CONN_N ro — TCPC audio accessory connect 0: audio accessory connected 1: No audio accessory connected
  [20] TCPC1_ACT_CABLE_CONN_N ro — TCPC active cable connect 0: No connected 1: Active cable connected
  [19:18] TCPC1_MUX_CTRL ro — TCPC MUX CTRL 0: No connect 1: USB3.1 connect 2: DP 4 lanes 3: USB3.1 and DP 2 lanes
  [17] TCPC1_CONN_PRESENT ro — TCPC connect present 0: No connect 1: Connected
  [16] TCPC1_CONN_ORIENTATION ro — TCPC connect orientation 0: normal 1: flip
  [11] TCPC0_VBUS_OVERCURRENT_EN rw — TCPC vbus over current enable 1: enable
  [10] TCPC0_VCONN_OVERCURRENT_EN ro — TCPC vconn overcurrent enable 1: enable
  [9] TCPC0_VBUS_VOLTAGE_EN ro — TCPC vbus voltage enable 1: enable
  [8] TCPC0_VBUS_OVERVOLTAGE_EN ro — TCPC vbus overvoltage enable 1: enable
  [7] TCPC0_OUTS_TO_HIZ ro — TCPC outs to hiz
  [6] TCPC0_DBG_ACC_CONN_N ro — TCPC debug accessory connect 0: Debug accessory connected 1: No debug accessory connected
  [5] TCPC0_AUDIO_ACC_CONN_N ro — TCPC audio accessory connect 0: audio accessory connected 1: No audio accessory connected
  [4] TCPC0_ACT_CABLE_CONN_N ro — TCPC active cable connect 0: No connected 1: Active cable connected
  [3:2] TCPC0_MUX_CTRL ro — TCPC MUX CTRL 0: No connect 1: USB3.1 connect 2: DP 4 lanes 3: USB3.1 and DP 2 lanes
  [1] TCPC0_CONN_PRESENT ro — TCPC connect present 0: No connect 1: Connected
  [0] TCPC0_CONN_ORIENTATION ro — TCPC connect orientation 0: normal 1: flip
0xE600 GRF_DLL_CON0 — pvtm control register
  [31:16] WRITE_ENABLE — bit0~15 write enable When bit 16=1, bit 0 can be written by software . When bit 16=0, bit 0 cannot be written by software; When bit 17=1, bit 1 can be written by software . When bit 17=0, bit 1 cannot be written by software; ...... When bit 31=1, bit 15 can be written by software . When bit 31=0, bit 15 cannot be written by software;
  [15:14] PVTM_GPU_OSC_RING_SEL — gpu PVT monitor oscilator ring select
  [13] PVTM_GPU_OSC_EN — gpu PVT monitor oscilator enable 1\'b1: enable 1\'b0: disable
  [12] PVTM_GPU_START — gpu PVT monitor start control
  [11:10] PVTM_DDR_OSC_RING_SEL — ddr PVT monitor oscilator ring select
  [9] PVTM_DDR_OSC_EN — ddr PVT monitor oscilator enable 1\'b1: enable 1\'b0: disable
  [8] PVTM_DDR_START — ddr PVT monitor start control
  [7:6] PVTM_CORE_B_OSC_SEL — pd_core_l PVT monitor oscilator select pvtm_core_b_osc_sel[1:0]
  [5] PVTM_CORE_B_OSC_EN — pd_core_b PVT monitor oscilator enable 1\'b1: enable 1\'b0: disable
  [4] PVTM_CORE_B_START — pd_core_b PVT monitor start control
  [3:2] PVTM_CORE_L_OSC_SEL — pd_core_l PVT monitor oscilator select
  [1] PVTM_CORE_L_OSC_EN — pd_core_l PVT monitor oscilator enable 1\'b1: enable 1\'b0: disable
  [0] PVTM_CORE_L_START — pd_core_l PVT monitor start control
0xE604 GRF_DLL_CON1 reset 0x16E3600 — pvtm control register
  [31:0] PVTM_CORE_L_CAL_CNT — pd_core_l pvtm calculator counter
0xE608 GRF_DLL_CON2 reset 0x16E3600 — pvtm control register
  [31:0] PVTM_CORE_B_CAL_CNT — pd_core_b pvtm calculator counter
0xE60C GRF_DLL_CON3 reset 0x16E3600 — pvtm control register
  [31:0] PVTM_DDR_CAL_CNT — ddr pvtm calculator counter
0xE610 GRF_DLL_CON4 reset 0x16E3600 — pvtm control register
  [31:0] PVTM_GPU_CAL_CNT — gpu pvtm calculator counter
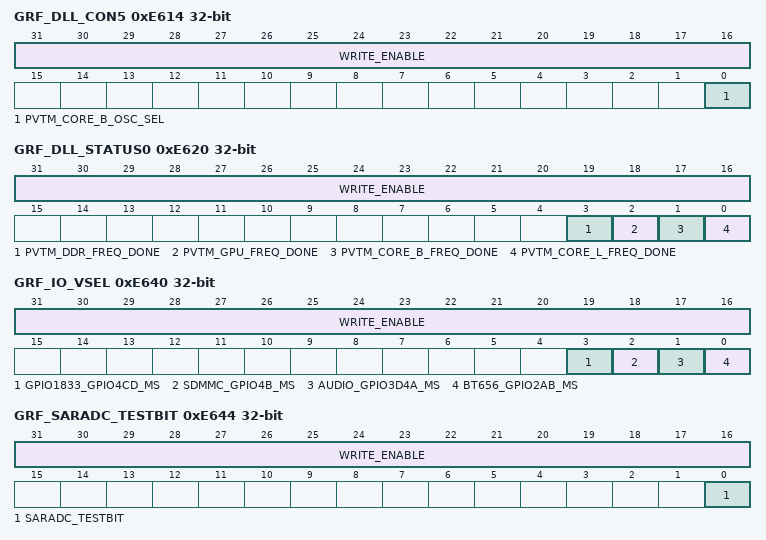
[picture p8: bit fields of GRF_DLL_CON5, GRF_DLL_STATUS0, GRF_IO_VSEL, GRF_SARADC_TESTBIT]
0xE614 GRF_DLL_CON5 — pvtm control register
  [31:16] WRITE_ENABLE — bit0~15 write enable When bit 16=1, bit 0 can be written by software . When bit 16=0, bit 0 cannot be written by software; When bit 17=1, bit 1 can be written by software . When bit 17=0, bit 1 cannot be written by software; ...... When bit 31=1, bit 15 can be written by software . When bit 31=0, bit 15 cannot be written by software;
  [0] PVTM_CORE_B_OSC_SEL — pvtm_core_b_osc_sel[2]
0xE620 GRF_DLL_STATUS0 — pvtm status register
  [31:16] WRITE_ENABLE — bit0~15 write enable When bit 16=1, bit 0 can be written by software . When bit 16=0, bit 0 cannot be written by software; When bit 17=1, bit 1 can be written by software . When bit 17=0, bit 1 cannot be written by software; ...... When bit 31=1, bit 15 can be written by software . When bit 31=0, bit 15 cannot be written by software;
  [3] PVTM_DDR_FREQ_DONE — ddr pvtm frequency calculate done stutus
  [2] PVTM_GPU_FREQ_DONE — gpu pvtm frequency calculate done stutus
  [1] PVTM_CORE_B_FREQ_DONE — pd_core_b pvtm frequency calculate done stutus
  [0] PVTM_CORE_L_FREQ_DONE — pd_core_l pvtm frequency calculate done stutus
0xE624 GRF_DLL_STATUS1 — pvtm status register
  [31:0] PVTM_CORE_L_FREQ_CNT — pd_core_l pvtm frequency count
0xE628 GRF_DLL_STATUS2 — pvtm status register
  [31:0] PVTM_CORE_B_FREQ_CNT — pd_core_b pvtm frequency count
0xE62C GRF_DLL_STATUS3 — pvtm status register
  [31:0] PVTM_GPU_FREQ_CNT — gpu pvtm frequency count
0xE630 GRF_DLL_STATUS4 — pvtm status register
  [31:0] PVTM_DDR_FREQ_CNT — ddr pvtm frequency count
0xE640 GRF_IO_VSEL
  [31:16] WRITE_ENABLE — bit0~15 write enable When bit 16=1, bit 0 can be written by software . When bit 16=0, bit 0 cannot be written by software; When bit 17=1, bit 1 can be written by software . When bit 17=0, bit 1 cannot be written by software; ...... When bit 31=1, bit 15 can be written by software . When bit 31=0, bit 15 cannot be written by software;
  [3] GPIO1833_GPIO4CD_MS
  [2] SDMMC_GPIO4B_MS
  [1] AUDIO_GPIO3D4A_MS
  [0] BT656_GPIO2AB_MS
0xE644 GRF_SARADC_TESTBIT — saradc test bit control register
  [31:16] WRITE_ENABLE — bit0~15 write enable When bit 16=1, bit 0 can be written by software . When bit 16=0, bit 0 cannot be written by software; When bit 17=1, bit 1 can be written by software . When bit 17=0, bit 1 cannot be written by software; ...... When bit 31=1, bit 15 can be written by software . When bit 31=0, bit 15 cannot be written by software;
  [0] SARADC_TESTBIT — saradc test bit control
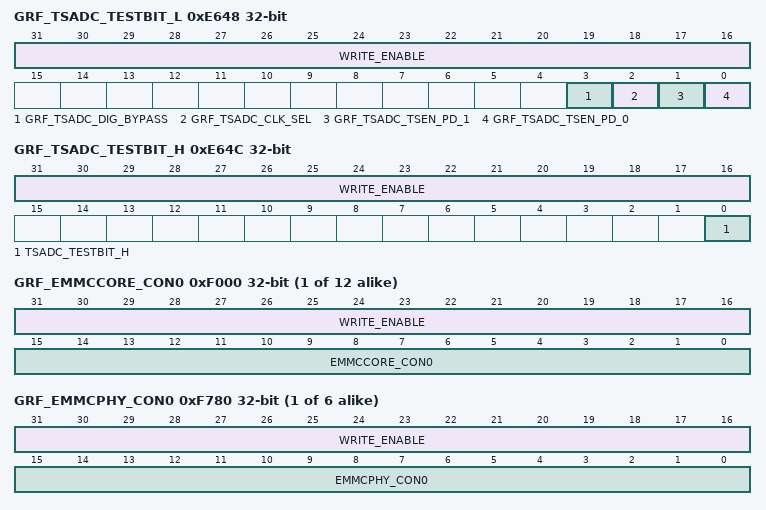
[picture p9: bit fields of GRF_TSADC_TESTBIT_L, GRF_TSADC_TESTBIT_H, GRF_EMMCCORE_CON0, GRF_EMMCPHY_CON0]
0xE648 GRF_TSADC_TESTBIT_L — saradc test bit control register
  [31:16] WRITE_ENABLE — bit0~15 write enable When bit 16=1, bit 0 can be written by software . When bit 16=0, bit 0 cannot be written by software; When bit 17=1, bit 1 can be written by software . When bit 17=0, bit 1 cannot be written by software; ...... When bit 31=1, bit 15 can be written by software . When bit 31=0, bit 15 cannot be written by software;
  [3] GRF_TSADC_DIG_BYPASS
  [2] GRF_TSADC_CLK_SEL
  [1] GRF_TSADC_TSEN_PD_1
  [0] GRF_TSADC_TSEN_PD_0
0xE64C GRF_TSADC_TESTBIT_H — tsadc test bit control register
  [31:16] WRITE_ENABLE — bit0~15 write enable When bit 16=1, bit 0 can be written by software . When bit 16=0, bit 0 cannot be written by software; When bit 17=1, bit 1 can be written by software . When bit 17=0, bit 1 cannot be written by software; ...... When bit 31=1, bit 15 can be written by software . When bit 31=0, bit 15 cannot be written by software;
  [0] TSADC_TESTBIT_H — tsadc test bit control
0xE800 GRF_CHIP_ID_ADDR — chip id register
  [31:0] CHIP_ID — 3399
0xE880 GRF_FAST_BOOT_ADDR — faster boot address register
  [31:0] FAST_BOOT_ADDR — fast boot address
{0xF000+4i} GRF_EMMCCORE_CON{i} (i=0..11) — emmc core control register
  [31:16] WRITE_ENABLE — bit0~15 write enable When bit 16=1, bit 0 can be written by software . When bit 16=0, bit 0 cannot be written by software; When bit 17=1, bit 1 can be written by software . When bit 17=0, bit 1 cannot be written by software; ...... When bit 31=1, bit 15 can be written by software . When bit 31=0, bit 15 cannot be written by software;
  [15:0] EMMCCORE_CON{i} — emmc controller control register {i}
{0xF040+4i} GRF_EMMCCORE_STATUS{i} (i=0..3) — emmc core status register
  [31:0] EMMCCORE_STATUS{i} — emmc controller status register {i}
{0xF780+4i} GRF_EMMCPHY_CON{i} (i=0..5) — emmc phy control register
  [31:16] WRITE_ENABLE — bit0~15 write enable When bit 16=1, bit 0 can be written by software . When bit 16=0, bit 0 cannot be written by software; When bit 17=1, bit 1 can be written by software . When bit 17=0, bit 1 cannot be written by software; ...... When bit 31=1, bit 15 can be written by software . When bit 31=0, bit 15 cannot be written by software;
  [15:0] EMMCPHY_CON{i} — emmc phy control register {i}
0xF798 GRF_EMMCPHY_CON6 — emmc phy control register
  [15:0] EMMCPHY_CON6 — emmc phy control register 5
0xF7A0 GRF_EMMCPHY_STATUS — emmc phy status register
  [31:0] EMMCPHY_STATUS
